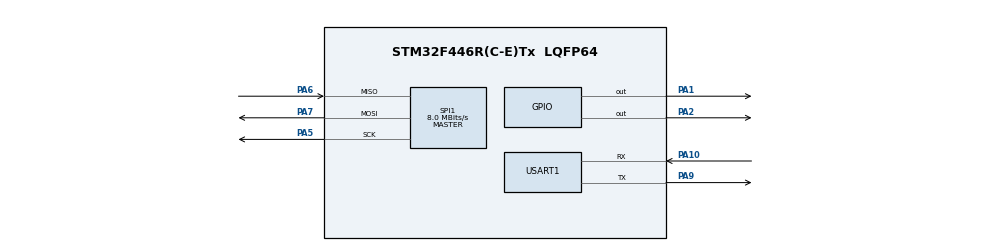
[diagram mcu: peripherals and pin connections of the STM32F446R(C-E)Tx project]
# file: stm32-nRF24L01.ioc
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FREERTOS.Tasks01=defaultTask,0,128,StartDefaultTask,Default,NULL
Mcu.Family=STM32F4
Mcu.Name=STM32F446R(C-E)Tx
Mcu.Package=LQFP64
NVIC.PriorityGroup=NVIC_PRIORITYGROUP_4
NVIC.TIM1_UP_TIM10_IRQn=true\:0\:0\:false\:false\:true\:false\:false
NVIC.TimeBase=TIM1_UP_TIM10_IRQn
NVIC.TimeBaseIP=TIM1
PA1.GPIO_PuPd=GPIO_PULLDOWN
PA1.Signal=GPIO_Output
PA10.Mode=Asynchronous
PA10.Signal=USART1_RX
PA2.GPIO_PuPd=GPIO_PULLDOWN
PA2.Signal=GPIO_Output
PA5.Mode=Full_Duplex_Master
PA5.Signal=SPI1_SCK
PA6.Mode=Full_Duplex_Master
PA6.Signal=SPI1_MISO
PA7.Mode=Full_Duplex_Master
PA7.Signal=SPI1_MOSI
PA9.Mode=Asynchronous
PA9.Signal=USART1_TX
ProjectManager.HeapSize=0x200
ProjectManager.StackSize=0x400
ProjectManager.TargetToolchain=Makefile
RCC.CortexFreq_Value=16000000
RCC.USBFreq_Value=96000000
RCC.VCOOutputFreq_Value=192000000
SPI1.CalculateBaudRate=8.0 MBits/s
SPI1.Direction=SPI_DIRECTION_2LINES
SPI1.Mode=SPI_MODE_MASTER
SPI1.VirtualType=VM_MASTER
USART1.VirtualMode=VM_ASYNC
VP_FREERTOS_VS_ENABLE.Mode=Enabled
VP_SYS_VS_tim1.Mode=TIM1
board=custom

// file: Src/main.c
/**
  ******************************************************************************
  * @file           : main.c
  * @brief          : Main program body
  ******************************************************************************
  * This notice applies to any and all portions of this file
  * that are not between comment pairs USER CODE BEGIN and
  * USER CODE END. Other portions of this file, whether
  * inserted by the user or by software development tools
  * are owned by their respective copyright owners.
  *
  * Copyright (c) 2018 STMicroelectronics International N.V.
  * All rights reserved.
  *
  * Redistribution and use in source and binary forms, with or without
  * modification, are permitted, provided that the following conditions are met:
  *
  * 1. Redistribution of source code must retain the above copyright notice,
  *    this list of conditions and the following disclaimer.
  * 2. Redistributions in binary form must reproduce the above copyright notice,
  *    this list of conditions and the following disclaimer in the documentation
  *    and/or other materials provided with the distribution.
  * 3. Neither the name of STMicroelectronics nor the names of other
  *    contributors to this software may be used to endorse or promote products
  *    derived from this software without specific written permission.
  * 4. This software, including modifications and/or derivative works of this
  *    software, must execute solely and exclusively on microcontroller or
  *    microprocessor devices manufactured by or for STMicroelectronics.
  * 5. Redistribution and use of this software other than as permitted under
  *    this license is void and will automatically terminate your rights under
  *    this license.
  *
  * THIS SOFTWARE IS PROVIDED BY STMICROELECTRONICS AND CONTRIBUTORS "AS IS"
  * AND ANY EXPRESS, IMPLIED OR STATUTORY WARRANTIES, INCLUDING, BUT NOT
  * LIMITED TO, THE IMPLIED WARRANTIES OF MERCHANTABILITY, FITNESS FOR A
  * PARTICULAR PURPOSE AND NON-INFRINGEMENT OF THIRD PARTY INTELLECTUAL PROPERTY
  * RIGHTS ARE DISCLAIMED TO THE FULLEST EXTENT PERMITTED BY LAW. IN NO EVENT
  * SHALL STMICROELECTRONICS OR CONTRIBUTORS BE LIABLE FOR ANY DIRECT, INDIRECT,
  * INCIDENTAL, SPECIAL, EXEMPLARY, OR CONSEQUENTIAL DAMAGES (INCLUDING, BUT NOT
  * LIMITED TO, PROCUREMENT OF SUBSTITUTE GOODS OR SERVICES; LOSS OF USE, DATA,
  * OR PROFITS; OR BUSINESS INTERRUPTION) HOWEVER CAUSED AND ON ANY THEORY OF
  * LIABILITY, WHETHER IN CONTRACT, STRICT LIABILITY, OR TORT (INCLUDING
  * NEGLIGENCE OR OTHERWISE) ARISING IN ANY WAY OUT OF THE USE OF THIS SOFTWARE,
  * EVEN IF ADVISED OF THE POSSIBILITY OF SUCH DAMAGE.
  *
  ******************************************************************************
  */
#include "main.h"
#include "stm32f4xx_hal.h"
#include "cmsis_os.h"
#include "radio.h"
#include <string.h>

#define RX_ONLY

SPI_HandleTypeDef hspi1;

UART_HandleTypeDef huart1;

osThreadId defaultTaskHandle;

/* USER CODE BEGIN PV */
/* Private variables ---------------------------------------------------------*/

/* USER CODE END PV */

void SystemClock_Config(void);
static void MX_GPIO_Init(void);
static void MX_SPI1_Init(void);
static void MX_USART1_UART_Init(void);
void StartDefaultTask(void const * argument);

/* USER CODE BEGIN PFP */
/* Private function prototypes -----------------------------------------------*/

/* USER CODE END PFP */

int main(void)
{

  /* MCU Configuration----------------------------------------------------------*/

  /* Reset of all peripherals, Initializes the Flash interface and the Systick. */
  HAL_Init();

  /* Configure the system clock */
  SystemClock_Config();

  /* Initialize all configured peripherals */
  MX_GPIO_Init();
  MX_SPI1_Init();
  MX_USART1_UART_Init();

  /* USER CODE BEGIN 2 */
  radio_configure();
  // tx
#ifndef RX_ONLY
  radio_configure_tx();
#endif

  /* USER CODE END 2 */

  /* Create the thread(s) */
  /* definition and creation of defaultTask */
  osThreadDef(defaultTask, StartDefaultTask, osPriorityNormal, 0, 128);
  defaultTaskHandle = osThreadCreate(osThread(defaultTask), NULL);

  /* Start scheduler */
  osKernelStart();

  /* We should never get here as control is now taken by the scheduler */

  /* Infinite loop */
  while (1)
  {

  }

}

void SystemClock_Config(void)
{

  RCC_OscInitTypeDef RCC_OscInitStruct;
  RCC_ClkInitTypeDef RCC_ClkInitStruct;

    /**Configure the main internal regulator output voltage
    */
  __HAL_RCC_PWR_CLK_ENABLE();

  __HAL_PWR_VOLTAGESCALING_CONFIG(PWR_REGULATOR_VOLTAGE_SCALE3);

    /**Initializes the CPU, AHB and APB busses clocks
    */
  RCC_OscInitStruct.OscillatorType = RCC_OSCILLATORTYPE_HSI;
  RCC_OscInitStruct.HSIState = RCC_HSI_ON;
  RCC_OscInitStruct.HSICalibrationValue = 16;
  RCC_OscInitStruct.PLL.PLLState = RCC_PLL_NONE;
  if (HAL_RCC_OscConfig(&RCC_OscInitStruct) != HAL_OK)
  {
    _Error_Handler(__FILE__, __LINE__);
  }

    /**Initializes the CPU, AHB and APB busses clocks
    */
  RCC_ClkInitStruct.ClockType = RCC_CLOCKTYPE_HCLK|RCC_CLOCKTYPE_SYSCLK
                              |RCC_CLOCKTYPE_PCLK1|RCC_CLOCKTYPE_PCLK2;
  RCC_ClkInitStruct.SYSCLKSource = RCC_SYSCLKSOURCE_HSI;
  RCC_ClkInitStruct.AHBCLKDivider = RCC_SYSCLK_DIV1;
  RCC_ClkInitStruct.APB1CLKDivider = RCC_HCLK_DIV1;
  RCC_ClkInitStruct.APB2CLKDivider = RCC_HCLK_DIV1;

  if (HAL_RCC_ClockConfig(&RCC_ClkInitStruct, FLASH_LATENCY_0) != HAL_OK)
  {
    _Error_Handler(__FILE__, __LINE__);
  }

    /**Configure the Systick interrupt time
    */
  HAL_SYSTICK_Config(HAL_RCC_GetHCLKFreq()/1000);

    /**Configure the Systick
    */
  HAL_SYSTICK_CLKSourceConfig(SYSTICK_CLKSOURCE_HCLK);

  /* SysTick_IRQn interrupt configuration */
  HAL_NVIC_SetPriority(SysTick_IRQn, 15, 0);
}

/* SPI1 init function */
static void MX_SPI1_Init(void)
{

  /* SPI1 parameter configuration*/
  hspi1.Instance = SPI1;
  hspi1.Init.Mode = SPI_MODE_MASTER;
  hspi1.Init.Direction = SPI_DIRECTION_2LINES;
  hspi1.Init.DataSize = SPI_DATASIZE_8BIT;
  hspi1.Init.CLKPolarity = SPI_POLARITY_LOW;
  hspi1.Init.CLKPhase = SPI_PHASE_1EDGE;
  hspi1.Init.NSS = SPI_NSS_SOFT;
  hspi1.Init.BaudRatePrescaler = SPI_BAUDRATEPRESCALER_2;
  hspi1.Init.FirstBit = SPI_FIRSTBIT_MSB;
  hspi1.Init.TIMode = SPI_TIMODE_DISABLE;
  hspi1.Init.CRCCalculation = SPI_CRCCALCULATION_DISABLE;
  hspi1.Init.CRCPolynomial = 10;
  if (HAL_SPI_Init(&hspi1) != HAL_OK)
  {
    _Error_Handler(__FILE__, __LINE__);
  }

}

/* USART1 init function */
static void MX_USART1_UART_Init(void)
{

  huart1.Instance = USART1;
  huart1.Init.BaudRate = 115200;
  huart1.Init.WordLength = UART_WORDLENGTH_8B;
  huart1.Init.StopBits = UART_STOPBITS_1;
  huart1.Init.Parity = UART_PARITY_NONE;
  huart1.Init.Mode = UART_MODE_TX_RX;
  huart1.Init.HwFlowCtl = UART_HWCONTROL_NONE;
  huart1.Init.OverSampling = UART_OVERSAMPLING_16;
  if (HAL_UART_Init(&huart1) != HAL_OK)
  {
    _Error_Handler(__FILE__, __LINE__);
  }

}

/** Configure pins as
        * Analog
        * Input
        * Output
        * EVENT_OUT
        * EXTI
*/
static void MX_GPIO_Init(void)
{

  GPIO_InitTypeDef GPIO_InitStruct;

  /* GPIO Ports Clock Enable */
  __HAL_RCC_GPIOA_CLK_ENABLE();

  /*Configure GPIO pin Output Level */
  HAL_GPIO_WritePin(GPIOA, GPIO_PIN_0|GPIO_PIN_1, GPIO_PIN_SET);

  /*Configure GPIO pins : PA0 PA1 */
  GPIO_InitStruct.Pin = GPIO_PIN_0|GPIO_PIN_1;
  GPIO_InitStruct.Mode = GPIO_MODE_OUTPUT_PP;
  GPIO_InitStruct.Pull = GPIO_PULLDOWN;
  GPIO_InitStruct.Speed = GPIO_SPEED_FREQ_LOW;
  HAL_GPIO_Init(GPIOA, &GPIO_InitStruct);

}

// tx default task
//  init();
//  uint8_t data[50] = {0};
//  char sendData[] = "aoeu";
//
//  enable_gpio(GPIO_A, GPIO_0);      // slave select
//  enable_gpio(GPIO_A, GPIO_1);      // chip enable
//
//  radio_configure();
//  radio_configure_tx();
//
//  while (1)
//  {
//    uint32_t i = 0;
//    memset(data, 0, sizeof(data));  // clear rx data
//
//    for (i = 0; i < 5000000; i++)
//    {
//      __asm__("nop");
//    }
//
//    // print on uart if rx data
//    radio_send((uint8_t *)sendData, sizeof(sendData));
//  }

/* StartDefaultTask function */
void StartDefaultTask(void const * argument)
{
#ifdef RX_ONLY
  // do RX
  uint8_t data[50] = {0};

  for(;;)
  {
    uint32_t i = 0;
    memset(data, 0, sizeof(data));  // clear rx data

    for (i = 0; i < 5000000; i++)
    {
      __asm__("nop");
    }

    // if rx data waiting, copy radio rx data to data buffer
    if (radio_rx_waiting() != 0x7)
    {
      radio_recv(data);
    }

    // print on uart if rx data
    if (data[0])
    {
      HAL_UART_Transmit(&huart1, data, sizeof(data), 10000);
    }

    osDelay(1);
  }
#else
  // do TX
  char sendData[] = "aoeu";

  /* Infinite loop */
  for(;;)
  {
    uint32_t i = 0;

    for (i = 0; i < 5000000; i++)
    {
      __asm__("nop");
    }

    // print on uart if rx data
    radio_send((uint8_t *)sendData, sizeof(sendData));

    osDelay(1);
  }
#endif
}

void HAL_TIM_PeriodElapsedCallback(TIM_HandleTypeDef *htim)
{
  if (htim->Instance == TIM1) {
    HAL_IncTick();
  }
}

void _Error_Handler(char *file, int line)
{
  while(1)
  {
  }
}

/************************ (C) COPYRIGHT STMicroelectronics *****END OF FILE****/
